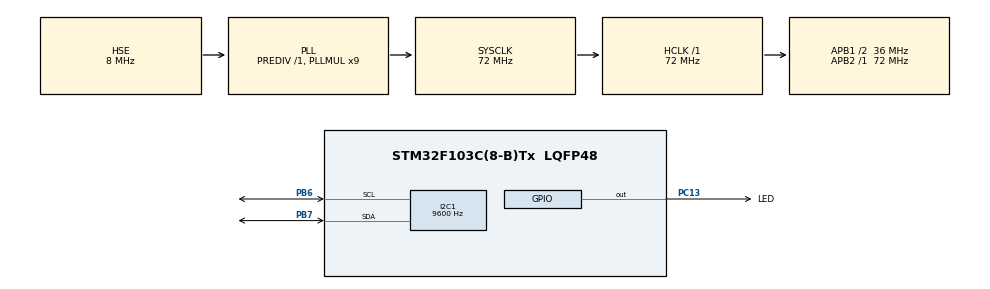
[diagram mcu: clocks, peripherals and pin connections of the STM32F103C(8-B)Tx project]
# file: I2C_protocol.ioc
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I2C1.ClockSpeed=9600
Mcu.Family=STM32F1
Mcu.Name=STM32F103C(8-B)Tx
Mcu.Package=LQFP48
NVIC.I2C1_ER_IRQn=true\:0\:0\:false\:false\:true\:true\:true\:true
NVIC.I2C1_EV_IRQn=true\:0\:0\:false\:false\:true\:true\:true\:true
NVIC.PriorityGroup=NVIC_PRIORITYGROUP_4
PA13.Mode=Serial_Wire
PA13.Signal=SYS_JTMS-SWDIO
PA14.Mode=Serial_Wire
PA14.Signal=SYS_JTCK-SWCLK
PB6.Mode=I2C
PB6.Signal=I2C1_SCL
PB7.Mode=I2C
PB7.Signal=I2C1_SDA
PC13-TAMPER-RTC.GPIO_Label=LED
PC13-TAMPER-RTC.Signal=GPIO_Output
PD0-OSC_IN.Mode=HSE-External-Oscillator
PD0-OSC_IN.Signal=RCC_OSC_IN
PD1-OSC_OUT.Mode=HSE-External-Oscillator
PD1-OSC_OUT.Signal=RCC_OSC_OUT
ProjectManager.HeapSize=0x200
ProjectManager.StackSize=0x400
ProjectManager.TargetToolchain=STM32CubeIDE
RCC.AHBFreq_Value=72000000
RCC.APB1CLKDivider=RCC_HCLK_DIV2
RCC.APB1Freq_Value=36000000
RCC.APB1TimFreq_Value=72000000
RCC.APB2Freq_Value=72000000
RCC.APB2TimFreq_Value=72000000
RCC.HCLKFreq_Value=72000000
RCC.PLLMUL=RCC_PLL_MUL9
RCC.PLLSourceVirtual=RCC_PLLSOURCE_HSE
RCC.SYSCLKFreq_VALUE=72000000
RCC.SYSCLKSource=RCC_SYSCLKSOURCE_PLLCLK
RCC.USBFreq_Value=72000000
board=custom

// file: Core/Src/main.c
/* USER CODE BEGIN Header */
/**
  ******************************************************************************
  * @file           : main.c
  * @brief          : Main program body
  ******************************************************************************
  * @attention
  *
  * Copyright (c) 2024 STMicroelectronics.
  * All rights reserved.
  *
  * This software is licensed under terms that can be found in the LICENSE file
  * in the root directory of this software component.
  * If no LICENSE file comes with this software, it is provided AS-IS.
  *
  ******************************************************************************
  */
/* USER CODE END Header */
#include "main.h"
#include "i2c.h"
#include "gpio.h"

/* USER CODE BEGIN Includes */
#include "stdbool.h"
#include "stdio.h"
#include <string.h>
/* USER CODE END Includes */

/* USER CODE BEGIN PD */
#define DS3231_ADDRESS 0xD0
/* USER CODE END PD */

/* USER CODE BEGIN PV */
uint8_t buf[30] = {0};
uint8_t data[sizeof(buf)] = {0};
bool i2c_complete = false;

/* USER CODE END PV */

void SystemClock_Config(void);

/* USER CODE BEGIN 0 */
typedef struct
{
	uint8_t seconds;
	uint8_t minutes;
	uint8_t hour;
	uint8_t dayofweek;
	uint8_t dayofmonth;
	uint8_t month;
	uint8_t year;
}Time;
Time time;
/* USER CODE END 0 */

int main(void)
{

  /* MCU Configuration--------------------------------------------------------*/

  /* Reset of all peripherals, Initializes the Flash interface and the Systick. */
  HAL_Init();

  /* Configure the system clock */
  SystemClock_Config();

  /* Initialize all configured peripherals */
  MX_GPIO_Init();
  MX_I2C1_Init();
  /* USER CODE BEGIN 2 */
  Set_Time(00, 03, 14, 5, 3, 1, 19);

  //HAL_I2C_Master_Receive_IT(&hi2c1, DS3231_ADDRESS, buf, sizeof(buf));
  /* USER CODE END 2 */

  /* Infinite loop */
  /* USER CODE BEGIN WHILE */
  while (1)
  {
	  Get_Time();
//	  if(i2c_complete == true)
//	  {
//		  HAL_GPIO_TogglePin(LED_GPIO_Port, LED_Pin);
//		  HAL_Delay(300);
//		  i2c_complete = false;
//		  HAL_I2C_Master_Receive_IT(&hi2c1, DS3231_ADDRESS, buf, sizeof(buf));
//	  }

    /* USER CODE END WHILE */

  }
}

void SystemClock_Config(void)
{
  RCC_OscInitTypeDef RCC_OscInitStruct = {0};
  RCC_ClkInitTypeDef RCC_ClkInitStruct = {0};

  /** Initializes the RCC Oscillators according to the specified parameters
  * in the RCC_OscInitTypeDef structure.
  */
  RCC_OscInitStruct.OscillatorType = RCC_OSCILLATORTYPE_HSE;
  RCC_OscInitStruct.HSEState = RCC_HSE_ON;
  RCC_OscInitStruct.HSEPredivValue = RCC_HSE_PREDIV_DIV1;
  RCC_OscInitStruct.HSIState = RCC_HSI_ON;
  RCC_OscInitStruct.PLL.PLLState = RCC_PLL_ON;
  RCC_OscInitStruct.PLL.PLLSource = RCC_PLLSOURCE_HSE;
  RCC_OscInitStruct.PLL.PLLMUL = RCC_PLL_MUL9;
  if (HAL_RCC_OscConfig(&RCC_OscInitStruct) != HAL_OK)
  {
    Error_Handler();
  }

  /** Initializes the CPU, AHB and APB buses clocks
  */
  RCC_ClkInitStruct.ClockType = RCC_CLOCKTYPE_HCLK|RCC_CLOCKTYPE_SYSCLK
                              |RCC_CLOCKTYPE_PCLK1|RCC_CLOCKTYPE_PCLK2;
  RCC_ClkInitStruct.SYSCLKSource = RCC_SYSCLKSOURCE_PLLCLK;
  RCC_ClkInitStruct.AHBCLKDivider = RCC_SYSCLK_DIV1;
  RCC_ClkInitStruct.APB1CLKDivider = RCC_HCLK_DIV2;
  RCC_ClkInitStruct.APB2CLKDivider = RCC_HCLK_DIV1;

  if (HAL_RCC_ClockConfig(&RCC_ClkInitStruct, FLASH_LATENCY_2) != HAL_OK)
  {
    Error_Handler();
  }
}

/* USER CODE BEGIN 4 */
void HAL_I2C_MasterRxCpltCallback(I2C_HandleTypeDef *hi2c)
{
    if(hi2c == &hi2c1)
    {
    	memcpy(data,buf,sizeof(buf));
    	i2c_complete = true;
    }

}

uint8_t decToBcd(int val)
{
  return (uint8_t)( (val/10*16) + (val%10) );
}
// Convert binary coded decimal to normal decimal numbers
int bcdToDec(uint8_t val)
{
  return (int)( (val/16*10) + (val%16) );
}

void Set_Time (uint8_t sec, uint8_t min, uint8_t hour, uint8_t dow, uint8_t dom, uint8_t month, uint8_t year)
{
	uint8_t set_time[7];
	set_time[0] = decToBcd(sec);
	set_time[1] = decToBcd(min);
	set_time[2] = decToBcd(hour);
	set_time[3] = decToBcd(dow);
	set_time[4] = decToBcd(dom);
	set_time[5] = decToBcd(month);
	set_time[6] = decToBcd(year);

	HAL_I2C_Mem_Write(&hi2c1, DS3231_ADDRESS, 0x00, 1, set_time, 7, 1000);
}

void Get_Time (void)
{
	uint8_t get_time[7];
	HAL_I2C_Mem_Read(&hi2c1, DS3231_ADDRESS, 0x00, 1, get_time, 7, 1000);
	time.seconds = bcdToDec(get_time[0]);
	time.minutes = bcdToDec(get_time[1]);
	time.hour = bcdToDec(get_time[2]);
	time.dayofweek = bcdToDec(get_time[3]);
	time.dayofmonth = bcdToDec(get_time[4]);
	time.month = bcdToDec(get_time[5]);
	time.year = bcdToDec(get_time[6]);
}

/* USER CODE END 4 */

void Error_Handler(void)
{
  __disable_irq();
  while (1)
  {
  }
}
